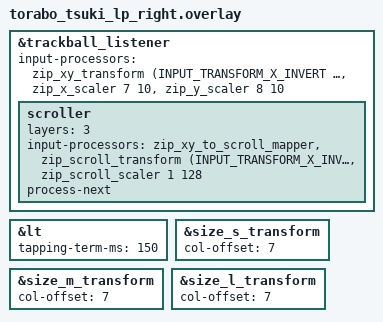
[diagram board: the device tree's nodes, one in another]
#include "torabo_tsuki_lp.dtsi"
#include <input/processors.dtsi>
#include <dt-bindings/zmk/input_transform.h>

&trackball_listener {
    input-processors = <&zip_xy_transform (INPUT_TRANSFORM_X_INVERT | INPUT_TRANSFORM_Y_INVERT)>, <&zip_x_scaler 7 10>, <&zip_y_scaler 8 10>;

	scroller {
	    layers = <3>;
        input-processors = <&zip_xy_to_scroll_mapper>, <&zip_scroll_transform (INPUT_TRANSFORM_X_INVERT)>, <&zip_scroll_scaler 1 128>;
        process-next;
    };
};

&lt {
    tapping-term-ms = <150>;
};

&size_s_transform {
    col-offset = <7>;
};

&size_m_transform {
    col-offset = <7>;
};

&size_l_transform {
    col-offset = <7>;
};
